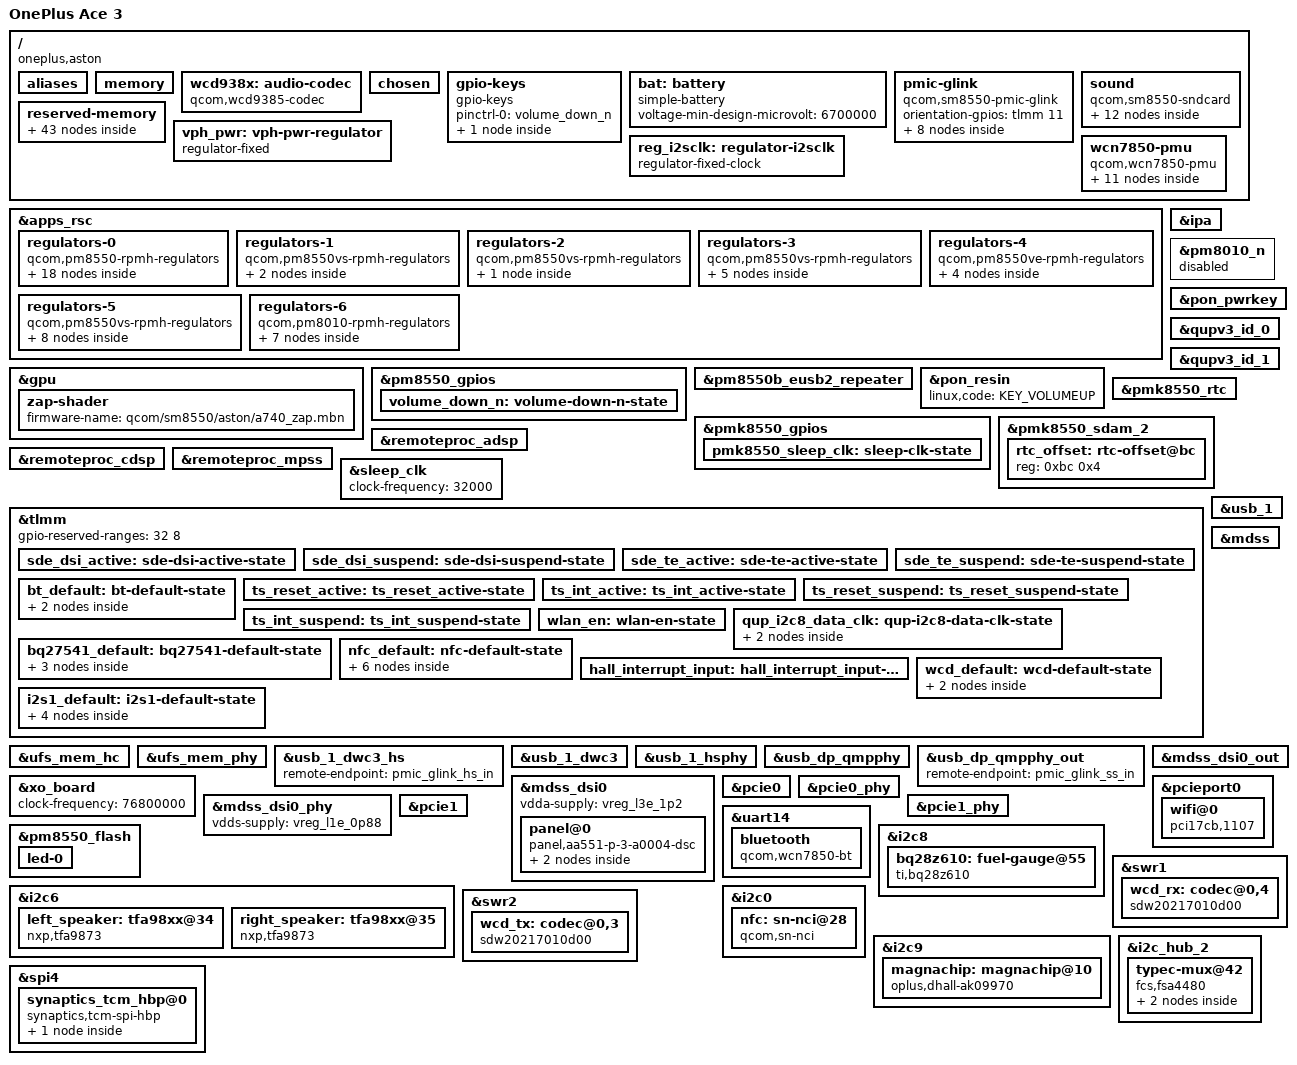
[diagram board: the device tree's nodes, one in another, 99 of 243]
// SPDX-License-Identifier: BSD-3-Clause
/*
 * Copyright (c) 2024, map220v <map220v300@gmail.com>
 */

/dts-v1/;

#include <dt-bindings/arm/qcom,ids.h>
#include <dt-bindings/regulator/qcom,rpmh-regulator.h>
#include <dt-bindings/leds/common.h>
#include "sm8550.dtsi"
#include "pm8010.dtsi"
#include "pm8550.dtsi"
#include "pm8550b.dtsi"
#define PMK8550VE_SID 5
#include "pm8550ve.dtsi"
#include "pm8550vs.dtsi"
#include "pmk8550.dtsi"

/* Remove wrong nodes */
/delete-node/ &rmtfs_mem;
/delete-node/ &adspslpi_mem;
/delete-node/ &mpss_mem;
/delete-node/ &trust_ui_vm_mem;
/delete-node/ &trust_ui_vm_qrtr;
/delete-node/ &oem_vm_vblk0_ring;
/delete-node/ &oem_vm_swiotlb;

/delete-node/ &trust_ui_vm_dump;
/delete-node/ &trust_ui_vm_vblk0_ring;
/delete-node/ &trust_ui_vm_vblk1_ring;
/delete-node/ &trust_ui_vm_swiotlb;
/delete-node/ &oem_vm_mem;

/delete-node/ &sdhc_2;

/ {
	model = "OnePlus Ace 3";
	compatible = "oneplus,aston", "qcom,sm8550";
	chassis-type = "handset";
	qcom,msm-id = <0x207 0x20000 0x207 0x10000 0x218 0x20000 0x218 0x10000>;
	qcom,board-id = <0x10008 0>;

	aliases {
		serial0 = &uart7;
		serial1 = &uart14;
	};
	
	memory {
		ddr_device_type = <0x08>;
		device_type = "memory";
		reg = <0x00 0x80000000 0x00 0xe00000 0x00 0x811d0000 0x00 0x56f90000 0x00 0xd8800000 0x00 0x00 0x00 0xe1bb0000 0x00 0x1e450000 0x08 0x80000000 0x00 0x38700000 0x08 0xc0000000 0x01 0x40000000 0x0a 0x00 0x02 0x00>;
	};
	
	wcd938x: audio-codec {
		compatible = "qcom,wcd9385-codec";

		pinctrl-names = "default", "sleep";
		pinctrl-0 = <&wcd_reset_n_sleep>;
		pinctrl-1 = <&wcd_reset_n_active>;

		qcom,micbias1-microvolt = <2700000>;
		qcom,micbias2-microvolt = <2700000>;
		qcom,micbias3-microvolt = <2700000>;
		qcom,micbias4-microvolt = <2700000>;
		qcom,mbhc-buttons-vthreshold-microvolt = <75000 150000 237000 500000 500000 500000 500000 500000>;
		qcom,mbhc-headset-vthreshold-microvolt = <1700000>;
		qcom,mbhc-headphone-vthreshold-microvolt = <50000>;
		qcom,rx-device = <&wcd_rx>;
		qcom,tx-device = <&wcd_tx>;

		reset-gpios = <&tlmm 108 GPIO_ACTIVE_LOW>;

		vdd-buck-supply = <&vreg_l15b_1p8>;
		vdd-rxtx-supply = <&vreg_l15b_1p8>;
		vdd-io-supply = <&vreg_l15b_1p8>;
		vdd-mic-bias-supply = <&vreg_bob1>;

		#sound-dai-cells = <1>;
	};
	
	chosen {
		#address-cells = <2>;
		#size-cells = <2>;
		ranges;
	};

	gpio-keys {
		compatible = "gpio-keys";

		pinctrl-0 = <&volume_down_n>;
		pinctrl-names = "default";

		key-volume-down {
			label = "Volume Down";
			linux,code = <KEY_VOLUMEDOWN>;
			gpios = <&pm8550_gpios 6 GPIO_ACTIVE_LOW>;
			debounce-interval = <15>;
			linux,can-disable;
			wakeup-source;
		};
	};
	
	bat: battery {
		compatible = "simple-battery";
		voltage-min-design-microvolt = <6700000>;
	};

	pmic-glink {
		compatible = "qcom,sm8550-pmic-glink", "qcom,pmic-glink";
		#address-cells = <1>;
		#size-cells = <0>;
		orientation-gpios = <&tlmm 11 GPIO_ACTIVE_HIGH>;

		connector@0 {
			compatible = "usb-c-connector";
			reg = <0>;
			power-role = "dual";
			data-role = "dual";

			ports {
				#address-cells = <1>;
				#size-cells = <0>;

				port@0 {
					reg = <0>;

					pmic_glink_hs_in: endpoint {
						remote-endpoint = <&usb_1_dwc3_hs>;
					};
				};

				port@1 {
					reg = <1>;

					pmic_glink_ss_in: endpoint {
						remote-endpoint = <&usb_dp_qmpphy_out>;
					};
				};

				port@2 {
					reg = <2>;

					pmic_glink_sbu: endpoint {
						remote-endpoint = <&fsa4480_sbu_mux>;
					};
				};
			};
		};
	};
	
	sound {
		compatible = "qcom,sm8550-sndcard";
		model = "astonsnd";
		audio-routing = "IN1_HPHL", "HPHL_OUT",
				"IN2_HPHR", "HPHR_OUT",
				"AMIC1", "MIC BIAS1",
				"AMIC2", "MIC BIAS2",
				"AMIC3", "MIC BIAS3",
				"AMIC4", "MIC BIAS3",
				"AMIC5", "MIC BIAS4",
				"TX SWR_INPUT0", "ADC1_OUTPUT",
				"TX SWR_INPUT1", "ADC2_OUTPUT",
				"TX SWR_INPUT0", "ADC3_OUTPUT",
				"TX SWR_INPUT1", "ADC4_OUTPUT";

		pinctrl-0 = <&i2s1_default>; 
		pinctrl-names = "default";

		wcd-playback-dai-link {
			link-name = "WCD Playback";

			cpu {
				sound-dai = <&q6apmbedai RX_CODEC_DMA_RX_0>;
			};

			codec {
				sound-dai = <&wcd938x 0>, <&swr1 0>, <&lpass_rxmacro 0>;
			};

			platform {
				sound-dai = <&q6apm>;
			};
		};

		wcd-capture-dai-link {
			link-name = "WCD Capture";

			cpu {
				sound-dai = <&q6apmbedai TX_CODEC_DMA_TX_3>;
			};

			codec {
				sound-dai = <&wcd938x 1>, <&swr2 0>, <&lpass_txmacro 0>;
			};

			platform {
				sound-dai = <&q6apm>;
			};
		};
		
		secondary-rx-dai-link { 
			link-name = "Secondary MI2S Playback"; 
		  
			cpu { 
				sound-dai = <&q6apmbedai SECONDARY_MI2S_RX>; 
			}; 
		  
			platform { 
				sound-dai = <&q6apm>; 
			}; 
		  
			codec { 
				sound-dai = <&left_speaker>, <&right_speaker>; 
			}; 
		};
	};


	reserved-memory {
		#address-cells = <2>;
		#size-cells = <2>;
		ranges;
		
		hyp_mem: hyp-region@80000000 {
			no-map;
			reg = <0x00 0x80000000 0x00 0xa00000>;
		};

		cpusys_vm_mem: cpusys-vm-region@80a00000 {
			no-map;
			reg = <0x00 0x80a00000 0x00 0x400000>;
		};

		/* merged xbl_dt_log, xbl_ramdump, aop_image */
		xbl_dt_log_merged_mem: xbl-dt-log-merged-region@81a00000 {
			no-map;
			reg = <0x00 0x81a00000 0x00 0x260000>;
		};

		aop_cmd_db_mem: aop-cmd-db-region@81c60000 {
			compatible = "qcom,cmd-db";
			no-map;
			reg = <0x00 0x81c60000 0x00 0x20000>;
		};

		/* merged aop_config, tme_crash_dump, tme_log, uefi_log */
		aop_config_merged_mem: aop-config-merged-region@81c80000 {
			no-map;
			reg = <0x00 0x81c80000 0x00 0x74000>;
		};

		/* secdata region can be reused by apps */
		smem: smem@81d00000 {
			no-map;
			reg = <0x00 0x81d00000 0x00 0x200000>;
			hwlocks = <&tcsr_mutex 3>;
			compatible = "qcom,smem";
		};

		adsp_mhi_mem: adsp-mhi-region@81f00000 {
			no-map;
			reg = <0x00 0x81f00000 0x00 0x20000>;
		};

		global_sync_mem: global-sync-region@82600000 {
			no-map;
			reg = <0x00 0x82600000 0x00 0x100000>;
		};

		tz_stat_mem: tz-stat-region@82700000 {
			no-map;
			reg = <0x00 0x82700000 0x00 0x100000>;
		};

		mpss_mem: mpss-region@89800000 {
			no-map;
			reg = <0x00 0x8a800000 0x00 0x10800000>;
		};

		q6_mpss_dtb_mem: q6-mpss-dtb-region@9b000000 {
			no-map;
			reg = <0x00 0x9b000000 0x00 0x80000>;
		};

		ipa_fw_mem: ipa-fw-region@9b080000 {
			no-map;
			reg = <0x00 0x9b080000 0x00 0x10000>;
		};

		ipa_gsi_mem: ipa-gsi-region@9b090000 {
			no-map;
			reg = <0x00 0x9b090000 0x00 0xa000>;
		};

		gpu_micro_code_mem: gpu-micro-code-region@9b09a000 {
			no-map;
			reg = <0x00 0x9b09a000 0x00 0x2000>;
		};

		spss_region_mem: spss-region@9b100000 {
			no-map;
			reg = <0x00 0x9b100000 0x00 0x180000>;
		};

		/* First part of the "SPU secure shared memory" region */
		spu_tz_shared_mem: spu-tz-shared-region@9b280000 {
			no-map;
			reg = <0x00 0x9b280000 0x00 0x60000>;
		};

		/* Second part of the "SPU secure shared memory" region */
		spu_modem_shared_mem: spu-modem-shared-region@9b2e0000 {
			no-map;
			reg = <0x00 0x9b2e0000 0x00 0x20000>;
		};

		camera_mem: camera-region@9b300000 {
			no-map;
			reg = <0x00 0x9b300000 0x00 0x800000>;
		};

		video_mem: video-region@9bb00000 {
			no-map;
			reg = <0x00 0x9bb00000 0x00 0x700000>;
		};

		cvp_mem: cvp-region@9c200000 {
			no-map;
			reg = <0x00 0x9c200000 0x00 0x700000>;
		};

		cdsp_mem: cdsp-region@9c900000 {
			no-map;
			reg = <0x00 0x9c900000 0x00 0x2000000>;
		};

		q6_cdsp_dtb_mem: q6-cdsp-dtb-region@9e900000 {
			no-map;
			reg = <0x00 0x9e900000 0x00 0x80000>;
		};

		q6_adsp_dtb_mem: q6-adsp-dtb-region@9e980000 {
			no-map;
			reg = <0x00 0x9e980000 0x00 0x80000>;
		};

		adspslpi_mem: adspslpi-region@9ea00000 {
			no-map;
			reg = <0x00 0x9ea00000 0x00 0x4880000>;
		};
		
		rmtfs_mem: rmtfs-region@e8100000 {
			compatible = "qcom,rmtfs-mem";
			reg = <0x0 0xe8100000 0x0 0x280000>;
			no-map;

			qcom,client-id = <1>;
			qcom,vmid = <QCOM_SCM_VMID_MSS_MSA>;
		};

		mpss_dsm_mem: mpss-dsm-region@d4d00000 {
			no-map;
			reg = <0x00 0xd4d00000 0x00 0x3300000>;
		};

		tz_reserved_mem: tz-reserved-region@d8000000 {
			no-map;
			reg = <0x00 0xd8000000 0x00 0x100000>;
		};

		xbl_sc_mem: xbl-sc-region@d8100000 {
			no-map;
			reg = <0x00 0xd8100000 0x00 0x40000>;
		};

		cpucp_fw_mem: cpucp-fw-region@d8140000 {
			no-map;
			reg = <0x00 0xd8140000 0x00 0x1c0000>;
		};

		qtee_mem: qtee-region@d8300000 {
			no-map;
			reg = <0x00 0xd8300000 0x00 0x500000>;
		};

		hwfence_shbuf: hwfence-shbuf-region@e6440000 {
			no-map;
			reg = <0x00 0xe6440000 0x00 0x279000>;
		};

		trust_ui_vm_mem: trust-ui-vm-region@f3800000 {
			no-map;
			reg = <0x00 0xf3800000 0x00 0x40ee000>;
		};

		trust_ui_vm_dump: trust-ui-vm-dump-region@f78ee000 {
			no-map;
			reg = <0x00 0xf78ee000 0x00 0x1000>;
		};

		trust_ui_vm_qrtr: trust-ui-vm-qrt-region@f78ef000 {
			no-map;
			reg = <0x00 0xf78ef000 0x00 0x9000>;
		};

		trust_ui_vm_vblk0_ring: trust-ui-vm-vblk0-ring-region@f78f8000 {
			no-map;
			reg = <0x00 0xf78f8000 0x00 0x4000>;
		};

		trust_ui_vm_vblk1_ring: trust-ui-vm-vblk1-ring-region@f78fc000 {
			no-map;
			reg = <0x00 0xf78fc000 0x00 0x4000>;
		};

		trust_ui_vm_swiotlb: trust-ui-vm-swiotlb-region@f7900000 {
			no-map;
			reg = <0x00 0xf7900000 0x00 0x100000>;
		};

		oem_vm_vblk0_ring: oem-vm-vblk0-ring-region@f7afc000 {
			no-map;
			reg = <0x00 0xf7afc000 0x00 0x4000>;
		};

		oem_vm_swiotlb: oem-vm-swiotlb-region@f7b00000 {
			no-map;
			reg = <0x00 0xf7b00000 0x00 0x100000>;
		};

		llcc_lpi_region: llcc_lpi_region@ff800000 {
			no-map;
			reg = <0x00 0xff800000 0x00 0x600000>;
		};
		
		oem_vm_mem: oem-vm-region@f7c00000 {
			reg = <0x00 0xf7c00000 0x00 0x4800000>;
			no-map;
		};

		botloader_mem: botloader_mem@a7605000 {
			reg = <0x00 0xa7605000 0x00 0x8000>;
		};

		device_info_mem: device_info_mem@a4f00000 {
			reg = <0x00 0xa4f00000 0x00 0x8000>;
		};
	};

	vph_pwr: vph-pwr-regulator {
		compatible = "regulator-fixed";
		regulator-name = "vph_pwr";
		regulator-min-microvolt = <3700000>;
		regulator-max-microvolt = <3700000>;

		regulator-always-on;
		regulator-boot-on;
	};
	
	reg_i2sclk: regulator-i2sclk { 
		compatible = "regulator-fixed-clock"; 
		regulator-name = "I2S1"; 
		clocks = <&q6prmcc LPASS_CLK_ID_SEC_MI2S_IBIT LPASS_CLK_ATTRIBUTE_COUPLE_NO>; 
		assigned-clocks = <&q6prmcc LPASS_CLK_ID_SEC_MI2S_IBIT LPASS_CLK_ATTRIBUTE_COUPLE_NO>; 
		assigned-clock-rates = <1536000>; 
	 
		vin-supply = <&vph_pwr>; 
		regulator-always-on; 
		regulator-min-microvolt = <3700000>; 
		regulator-max-microvolt = <3700000>; 
		startup-delay-us = <150000>; 
	 }; 
	
	wcn7850-pmu {
		compatible = "qcom,wcn7850-pmu";

		pinctrl-names = "default";
		pinctrl-0 = <&wlan_en>, <&pmk8550_sleep_clk>;

		wlan-enable-gpios = <&tlmm 80 GPIO_ACTIVE_HIGH>;
		/*
		 * TODO Add bt-enable-gpios once the Bluetooth driver is
		 * converted to using the power sequencer.
		 */

		vdd-supply = <&vreg_s5g_0p8>;
		vddio-supply = <&vreg_l15b_1p8>; 
		vddaon-supply = <&vreg_s2g_0p8>;
		vdddig-supply = <&vreg_s4e_0p9>;
		vddrfa1p2-supply = <&vreg_s4g_1p3>;
		vddrfa1p8-supply = <&vreg_s6g_1p8>;

		regulators {
			vreg_pmu_rfa_cmn: ldo0 {
				regulator-name = "vreg_pmu_rfa_cmn";
			};

			vreg_pmu_aon_0p59: ldo1 {
				regulator-name = "vreg_pmu_aon_0p59";
			};

			vreg_pmu_wlcx_0p8: ldo2 {
				regulator-name = "vreg_pmu_wlcx_0p8";
			};

			vreg_pmu_wlmx_0p85: ldo3 {
				regulator-name = "vreg_pmu_wlmx_0p85";
			};

			vreg_pmu_btcmx_0p85: ldo4 {
				regulator-name = "vreg_pmu_btcmx_0p85";
			};

			vreg_pmu_rfa_0p8: ldo5 {
				regulator-name = "vreg_pmu_rfa_0p8";
			};

			vreg_pmu_rfa_1p2: ldo6 {
				regulator-name = "vreg_pmu_rfa_1p2";
			};

			vreg_pmu_rfa_1p8: ldo7 {
				regulator-name = "vreg_pmu_rfa_1p8";
			};

			vreg_pmu_pcie_0p9: ldo8 {
				regulator-name = "vreg_pmu_pcie_0p9";
			};

			vreg_pmu_pcie_1p8: ldo9 {
				regulator-name = "vreg_pmu_pcie_1p8";
			};
		};
	};
};

&apps_rsc {
	regulators-0 {
		compatible = "qcom,pm8550-rpmh-regulators";
		qcom,pmic-id = "b";

		vdd-bob1-supply = <&vph_pwr>;
		vdd-bob2-supply = <&vph_pwr>;
		vdd-l1-l4-l10-supply = <&vreg_s6g_1p8>;
		vdd-l2-l13-l14-supply = <&vreg_bob1>;
		vdd-l3-supply = <&vreg_s4g_1p3>;
		vdd-l5-l16-supply = <&vreg_bob1>;
		vdd-l6-l7-supply = <&vreg_bob1>;
		vdd-l8-l9-supply = <&vreg_bob1>;
		vdd-l11-supply = <&vreg_s4g_1p3>;
		vdd-l12-supply = <&vreg_s6g_1p8>;
		vdd-l15-supply = <&vreg_s6g_1p8>;
		vdd-l17-supply = <&vreg_bob2>;

		vreg_bob1: bob1 {
			regulator-name = "vreg_bob1";
			regulator-min-microvolt = <3008000>;
			regulator-max-microvolt = <3960000>;
			regulator-initial-mode = <RPMH_REGULATOR_MODE_HPM>;
		};

		vreg_bob2: bob2 {
			regulator-name = "vreg_bob2";
			regulator-min-microvolt = <2704000>;
			regulator-max-microvolt = <3008000>;
			regulator-initial-mode = <RPMH_REGULATOR_MODE_HPM>;
		};

		vreg_l1b_1p8: ldo1 {
			regulator-name = "vreg_l1b_1p8";
			regulator-min-microvolt = <1800000>;
			regulator-max-microvolt = <1800000>;
			regulator-initial-mode = <RPMH_REGULATOR_MODE_HPM>;
		};

		vreg_l2b_3p0: ldo2 {
			regulator-name = "vreg_l2b_3p0";
			regulator-min-microvolt = <3008000>;
			regulator-max-microvolt = <3008000>;
			regulator-initial-mode = <RPMH_REGULATOR_MODE_HPM>;
		};

		vreg_l4b_1p8: ldo4 {
			regulator-name = "vreg_l4b_1p8";
			regulator-min-microvolt = <1800000>;
			regulator-max-microvolt = <1800000>;
			regulator-initial-mode = <RPMH_REGULATOR_MODE_HPM>;
		};

		vreg_l5b_3p1: ldo5 {
			regulator-name = "vreg_l5b_3p1";
			regulator-min-microvolt = <3104000>;
			regulator-max-microvolt = <3104000>;
			regulator-initial-mode = <RPMH_REGULATOR_MODE_HPM>;
		};

		vreg_l6b_1p8: ldo6 {
			regulator-name = "vreg_l6b_1p8";
			regulator-min-microvolt = <1800000>;
			regulator-max-microvolt = <3008000>;
			regulator-initial-mode = <RPMH_REGULATOR_MODE_HPM>;
		};

		vreg_l7b_1p8: ldo7 {
			regulator-name = "vreg_l7b_1p8";
			regulator-min-microvolt = <1800000>;
			regulator-max-microvolt = <3008000>;
			regulator-initial-mode = <RPMH_REGULATOR_MODE_HPM>;
		};

		vreg_l8b_1p8: ldo8 {
			regulator-name = "vreg_l8b_1p8";
			regulator-min-microvolt = <1800000>;
			regulator-max-microvolt = <1800000>;
			regulator-initial-mode = <RPMH_REGULATOR_MODE_HPM>;
			regulator-always-on;
			regulator-boot-on;
		};

		vreg_l9b_3p3: ldo9 {
			regulator-name = "vreg_l9b_3p3";
			regulator-min-microvolt = <2960000>;
			regulator-max-microvolt = <3008000>;
			regulator-initial-mode = <RPMH_REGULATOR_MODE_HPM>;
		};

		vreg_l10b_1p8: ldo10 {
			regulator-name = "vreg_l10b_1p8";
			regulator-min-microvolt = <1800000>;
			regulator-max-microvolt = <1800000>;
			regulator-initial-mode = <RPMH_REGULATOR_MODE_HPM>;
		};

		vreg_l11b_1p2: ldo11 {
			regulator-name = "vreg_l11b_1p2";
			regulator-min-microvolt = <1200000>;
			regulator-max-microvolt = <1504000>;
			regulator-initial-mode = <RPMH_REGULATOR_MODE_HPM>;
		};

		vreg_l12b_1p8: ldo12 {
			regulator-name = "vreg_l12b_1p8";
			regulator-min-microvolt = <1800000>;
			regulator-max-microvolt = <1800000>;
			regulator-initial-mode = <RPMH_REGULATOR_MODE_HPM>;
		};

		vreg_l13b_3p3: ldo13 {
			regulator-name = "vreg_l13b_3p3";
			regulator-min-microvolt = <3000000>;
			regulator-max-microvolt = <3200000>;
			regulator-initial-mode = <RPMH_REGULATOR_MODE_HPM>;
		};

		vreg_l14b_3p2: ldo14 {
			regulator-name = "vreg_l14b_3p2";
			regulator-min-microvolt = <2800000>;
			regulator-max-microvolt = <3200000>;
			regulator-initial-mode = <RPMH_REGULATOR_MODE_HPM>;
		};
		
		vreg_l15b_1p8: ldo15 {
			regulator-name = "vreg_l15b_1p8";
			regulator-min-microvolt = <1800000>;
			regulator-max-microvolt = <1800000>;
			regulator-initial-mode = <RPMH_REGULATOR_MODE_HPM>;
		};

		vreg_l16b_2p8: ldo16 {
			regulator-name = "vreg_l16b_2p8";
			regulator-min-microvolt = <2800000>;
			regulator-max-microvolt = <2800000>;
			regulator-initial-mode = <RPMH_REGULATOR_MODE_HPM>;
		};

		vreg_l17b_2p5: ldo17 {
			regulator-name = "vreg_l17b_2p5";
			regulator-min-microvolt = <2504000>;
			regulator-max-microvolt = <2504000>;
			regulator-initial-mode = <RPMH_REGULATOR_MODE_HPM>;
		};
	};

	regulators-1 {
		compatible = "qcom,pm8550vs-rpmh-regulators";
		qcom,pmic-id = "c";

		vdd-l3-supply = <&vreg_s4e_0p9>;
		
		
		vreg_l1c_0p91: ldo1 {
			regulator-name = "vreg_l1c_0p9";
			regulator-min-microvolt = <1200000>;
			regulator-max-microvolt = <1200000>;
			regulator-initial-mode = <RPMH_REGULATOR_MODE_HPM>;
		};

		vreg_l3c_0p91: ldo3 {
			regulator-name = "vreg_l3c_0p9";
			regulator-min-microvolt = <880000>;
			regulator-max-microvolt = <912000>;
			regulator-initial-mode = <RPMH_REGULATOR_MODE_HPM>;
		};
	};

	regulators-2 {
		compatible = "qcom,pm8550vs-rpmh-regulators";
		qcom,pmic-id = "d";

		vdd-l1-supply = <&vreg_s4e_0p9>;

		vreg_l1d_0p88: ldo1 {
			regulator-name = "vreg_l1d_0p88";
			regulator-min-microvolt = <880000>;
			regulator-max-microvolt = <920000>;
			regulator-initial-mode = <RPMH_REGULATOR_MODE_HPM>;
		};
	};

	regulators-3 {
		compatible = "qcom,pm8550vs-rpmh-regulators";
		qcom,pmic-id = "e";

		vdd-l1-supply = <&vreg_s4e_0p9>;
		vdd-l2-supply = <&vreg_s4e_0p9>;
		vdd-l3-supply = <&vreg_s4g_1p3>;
		vdd-s4-supply = <&vph_pwr>;
		vdd-s5-supply = <&vph_pwr>;

		vreg_s4e_0p9: smps4 {
			regulator-name = "vreg_s4e_0p9";
			regulator-min-microvolt = <904000>;
			regulator-max-microvolt = <984000>;
			regulator-initial-mode = <RPMH_REGULATOR_MODE_HPM>;
		};

		vreg_s5e_1p1: smps5 {
			regulator-name = "vreg_s5e_1p1";
			regulator-min-microvolt = <1008000>;
			regulator-max-microvolt = <1120000>;
			regulator-initial-mode = <RPMH_REGULATOR_MODE_HPM>;
		};

		vreg_l1e_0p88: ldo1 {
			regulator-name = "vreg_l1e_0p88";
			regulator-min-microvolt = <880000>;
			regulator-max-microvolt = <912000>;
			regulator-initial-mode = <RPMH_REGULATOR_MODE_HPM>;
		};

		vreg_l2e_0p9: ldo2 {
			regulator-name = "vreg_l2e_0p9";
			regulator-min-microvolt = <864000>;
			regulator-max-microvolt = <970000>;
			regulator-initial-mode = <RPMH_REGULATOR_MODE_HPM>;
		};

		vreg_l3e_1p2: ldo3 {
			regulator-name = "vreg_l3e_1p2";
			regulator-min-microvolt = <1200000>;
			regulator-max-microvolt = <1200000>;
			regulator-initial-mode = <RPMH_REGULATOR_MODE_HPM>;
		};
	};

	regulators-4 {
		compatible = "qcom,pm8550ve-rpmh-regulators";
		qcom,pmic-id = "f";

		vdd-l1-supply = <&vreg_s4e_0p9>;
		vdd-l2-supply = <&vreg_s4e_0p9>;
		vdd-l3-supply = <&vreg_s4e_0p9>;
		vdd-s4-supply = <&vph_pwr>;

		vreg_s4f_0p5: smps4 {
			regulator-name = "vreg_s4f_0p5";
			regulator-min-microvolt = <300000>;
			regulator-max-microvolt = <700000>;
			regulator-initial-mode = <RPMH_REGULATOR_MODE_HPM>;
		};

		vreg_l1f_0p9: ldo1 {
			regulator-name = "vreg_l1f_0p9";
			regulator-min-microvolt = <880000>;
			regulator-max-microvolt = <912000>;
			regulator-initial-mode = <RPMH_REGULATOR_MODE_HPM>;
		};

		vreg_l2f_0p88: ldo2 {
			regulator-name = "vreg_l2f_0p88";
			regulator-min-microvolt = <880000>;
			regulator-max-microvolt = <912000>;
			regulator-initial-mode = <RPMH_REGULATOR_MODE_HPM>;
		};

		vreg_l3f_0p91: ldo3 {
			regulator-name = "vreg_l3f_0p91";
			regulator-min-microvolt = <880000>;
			regulator-max-microvolt = <912000>;
			regulator-initial-mode = <RPMH_REGULATOR_MODE_HPM>;
		};
	};

	regulators-5 {
		compatible = "qcom,pm8550vs-rpmh-regulators";
		qcom,pmic-id = "g";

		vdd-l1-supply = <&vreg_s4g_1p3>;
		vdd-l2-supply = <&vreg_s4g_1p3>;
		vdd-l3-supply = <&vreg_s4g_1p3>;
		vdd-s1-supply = <&vph_pwr>;
		vdd-s2-supply = <&vph_pwr>;
		vdd-s3-supply = <&vph_pwr>;
		vdd-s4-supply = <&vph_pwr>;
		vdd-s5-supply = <&vph_pwr>;
		vdd-s6-supply = <&vph_pwr>;

		vreg_s1g_1p2: smps1 {
			regulator-name = "vreg_s1g_1p2";
			regulator-min-microvolt = <1200000>;
			regulator-max-microvolt = <1300000>;
			regulator-initial-mode = <RPMH_REGULATOR_MODE_HPM>;
		};

		vreg_s2g_0p8: smps2 {
			regulator-name = "vreg_s2g_0p8";
			regulator-min-microvolt = <500000>;
			regulator-max-microvolt = <1036000>;
			regulator-initial-mode = <RPMH_REGULATOR_MODE_HPM>;
		};

		vreg_s4g_1p3: smps4 {
			regulator-name = "vreg_s4g_1p3";
			regulator-min-microvolt = <1200000>;
			regulator-max-microvolt = <1352000>;
			regulator-initial-mode = <RPMH_REGULATOR_MODE_HPM>;
		};

		vreg_s5g_0p8: smps5 {
			regulator-name = "vreg_s5g_0p8";
			regulator-min-microvolt = <500000>;
			regulator-max-microvolt = <1004000>;
			regulator-initial-mode = <RPMH_REGULATOR_MODE_HPM>;
		};

		vreg_s6g_1p8: smps6 {
			regulator-name = "vreg_s6g_1p8";
			regulator-min-microvolt = <1800000>;
			regulator-max-microvolt = <2000000>;
			regulator-initial-mode = <RPMH_REGULATOR_MODE_HPM>;
		};

		vreg_l1g_1p2: ldo1 {
			regulator-name = "vreg_l1g_1p2";
			regulator-min-microvolt = <1144000>;
			regulator-max-microvolt = <1256000>;
			regulator-initial-mode = <RPMH_REGULATOR_MODE_HPM>;
		};

		vreg_l2g_1p2: ldo2 {
			regulator-name = "vreg_l2g_1p2";
			regulator-min-microvolt = <1050000>;
			regulator-max-microvolt = <1200000>;
			regulator-initial-mode = <RPMH_REGULATOR_MODE_HPM>;
		};

		vreg_l3g_1p2: ldo3 {
			regulator-name = "vreg_l3g_1p2";
			regulator-min-microvolt = <1200000>;
			regulator-max-microvolt = <1200000>;
			regulator-initial-mode = <RPMH_REGULATOR_MODE_HPM>;
		};
	};

	regulators-6 {
		compatible = "qcom,pm8010-rpmh-regulators";
		qcom,pmic-id = "m";

		vdd-l1-l2-supply = <&vreg_s4g_1p3>;
		vdd-l3-l4-supply = <&vreg_bob2>;
		vdd-l5-supply = <&vreg_s6g_1p8>;
		vdd-l6-supply = <&vreg_s6g_1p8>;
		vdd-l7-supply = <&vreg_bob1>;

		vreg_l1m_1p2: ldo1 {
			regulator-name = "vreg_l1m_1p2";
			regulator-min-microvolt = <1200000>;
			regulator-max-microvolt = <1200000>;
			regulator-initial-mode = <RPMH_REGULATOR_MODE_HPM>;
		};

		vreg_l2m_1p08: ldo2 {
			regulator-name = "vreg_l2m_1p08";
			regulator-min-microvolt = <1200000>;
			regulator-max-microvolt = <1200000>;
			regulator-initial-mode = <RPMH_REGULATOR_MODE_HPM>;
		};

		vreg_l3m_2p8: ldo3 {
			regulator-name = "vreg_l3m_2p8";
			regulator-min-microvolt = <2200000>;
			regulator-max-microvolt = <3304000>;
			regulator-initial-mode = <RPMH_REGULATOR_MODE_HPM>;
		};

		vreg_l4m_2p8: ldo4 {
			regulator-name = "vreg_l4m_2p8";
			regulator-min-microvolt = <1800000>;
			regulator-max-microvolt = <3304000>;
			regulator-initial-mode = <RPMH_REGULATOR_MODE_HPM>;
		};

		vreg_l5m_1p8: ldo5 {
			regulator-name = "vreg_l5m_1p8";
			regulator-min-microvolt = <1800000>;
			regulator-max-microvolt = <1800000>;
			regulator-initial-mode = <RPMH_REGULATOR_MODE_HPM>;
		};

		vreg_l6m_2p8: ldo6 {
			regulator-name = "vreg_l6m_2p8";
			regulator-min-microvolt = <1800000>;
			regulator-max-microvolt = <3304000>;
			regulator-initial-mode = <RPMH_REGULATOR_MODE_HPM>;
		};

		vreg_l7m_2p85: ldo7 {
			regulator-name = "vreg_l7m_2p85";
			regulator-min-microvolt = <1800000>;
			regulator-max-microvolt = <3152000>;
			regulator-initial-mode = <RPMH_REGULATOR_MODE_HPM>;
		};
	};
};



&ipa {
	qcom,gsi-loader = "self";
	memory-region = <&ipa_gsi_mem>;
	firmware-name = "qcom/sm8550/aston/ipa_fws.mbn";
	status = "okay";
};

&gpu {
	status = "okay";

	zap-shader {
		firmware-name = "qcom/sm8550/aston/a740_zap.mbn";
	};
};

&pm8010_n {
	status = "disabled";
};

&pm8550_gpios {
	volume_down_n: volume-down-n-state {
		pins = "gpio6";
		function = "normal";
		power-source = <1>;
		bias-pull-up;
		input-enable;
	};
};

&pm8550b_eusb2_repeater {
	vdd18-supply = <&vreg_l15b_1p8>;
	vdd3-supply = <&vreg_l5b_3p1>;
};

&pon_pwrkey {
	status = "okay";
	interrupts = <0x0 0x13 0x7 IRQ_TYPE_EDGE_BOTH>;
    linux,code = <KEY_POWER>;
};

&pon_resin {
	linux,code = <KEY_VOLUMEUP>;

	status = "okay";
};

&pmk8550_gpios {
	pmk8550_sleep_clk: sleep-clk-state {
		pins = "gpio3";
		function = "func1";
		input-disable;
		output-enable;
		bias-disable;
		power-source = <0>;
	};
};

&qupv3_id_0 {
	status = "okay";
};

&qupv3_id_1 {
	status = "okay";
};

&pmk8550_rtc {
	nvmem-cells = <&rtc_offset>;
	nvmem-cell-names = "offset";
};

&pmk8550_sdam_2 {
	rtc_offset: rtc-offset@bc {
		reg = <0xbc 0x4>;
	};
};

&remoteproc_adsp {
	firmware-name = "qcom/sm8550/aston/adsp.mbn",
			"qcom/sm8550/aston/adsp_dtb.mbn";
	status = "okay";
};

&remoteproc_cdsp {
	firmware-name = "qcom/sm8550/aston/cdsp.mbn",
			"qcom/sm8550/aston/cdsp_dtb.mbn";
	status = "okay";
};

&remoteproc_mpss {
	firmware-name = "qcom/sm8550/aston/modem.mbn",
			"qcom/sm8550/aston/modem_dtb.mbn";
	status = "okay";
};

&sleep_clk {
	clock-frequency = <32000>;
};

&tlmm {
	gpio-reserved-ranges = <32 8>;

	sde_dsi_active: sde-dsi-active-state {
		pins = "gpio133";
		function = "gpio";
		drive-strength = <8>;
		bias-disable;
	};

	sde_dsi_suspend: sde-dsi-suspend-state {
		pins = "gpio133";
		function = "gpio";
		drive-strength = <2>;
		bias-pull-down;
	};
	
	sde_te_active: sde-te-active-state {
		pins = "gpio86";
		function = "mdp_vsync";
		drive-strength = <2>;
		bias-pull-down;
	};

	sde_te_suspend: sde-te-suspend-state {
		pins = "gpio86";
		function = "mdp_vsync";
		drive-strength = <2>;
		bias-pull-down;
	};

	bt_default: bt-default-state {
		bt-en-pins {
			pins = "gpio81";
			function = "gpio";
			drive-strength = <16>;
			bias-disable;
		};

		sw-ctrl-pins {
			pins = "gpio82";
			function = "gpio";
			bias-pull-down;
		};
	};
	
	ts_reset_active: ts_reset_active-state {
		pins = "gpio24";
		function = "gpio";
		bias-disable;
		output-low;
		drive-strength = <8>;
	};

	ts_int_active: ts_int_active-state {
		pins = "gpio25";
		function = "gpio";
		bias-pull-up;
		drive-strength = <8>;
		input-enable;
	};
	
	ts_reset_suspend: ts_reset_suspend-state {
		pins = "gpio24";
		function = "gpio";
		bias-pull-down;
		drive-strength = <2>;
	};

	ts_int_suspend: ts_int_suspend-state {
		pins = "gpio25";
		function = "gpio";
		bias-pull-down;
		drive-strength = <2>;
	};

	wlan_en: wlan-en-state {
		pins = "gpio80";
		function = "gpio";
		drive-strength = <8>;
		bias-pull-down;
	};

	qup_i2c8_data_clk: qup-i2c8-data-clk-state {
		scl-pins {
			pins = "gpio1";
			function = "qup2_se0_l1_mirb";
			drive-strength = <2>;
			bias-pull-up = <2200>;
		};

		sda-pins {
			pins = "gpio0";
			function = "qup2_se0_l0_mirb";
			drive-strength = <2>;
			bias-pull-up = <2200>;
		};
	};

	bq27541_default: bq27541-default-state {
		bq27541_id_not_pull: bq27541_id_not_pull-state {
			pins = "gpio73";
			function = "gpio";
			drive-strength = <2>;
			bias-disable;
		};
		
		bq27541_id_pull_up: bq27541_id_pull_up-state {
			pins = "gpio73";
			function = "gpio";
			drive-strength = <2>;
			bias-pull-up;
		};
		
		bq27541_id_pull_down: bq27541_id_pull_down-state {
			pins = "gpio73";
			function = "gpio";
			drive-strength = <2>;
			bias-pull-down;
		};
	};
	
	nfc_default: nfc-default-state {
		nfc_int_active: nfc_int_active-state {
			pins = "gpio55";
			function = "gpio";
			drive-strength = <2>;
			bias-pull-up;
		};
		nfc_enable_active: nfc_enable_active-state {
			pins = "gpio30";
			function = "gpio";
			drive-strength = <2>;
			bias-pull-up;
		};
		nfc_clk_req_active: nfc_clk_req_active-state {
			pins = "gpio31";
			function = "gpio";
			drive-strength = <2>;
			bias-pull-up;
		};
		nfc_int_suspend: nfc_int_suspend-state {
			pins = "gpio55";
			function = "gpio";
			drive-strength = <2>;
			bias-pull-up;
		};
		nfc_enable_suspend: nfc_enable_suspend-state {
			pins = "gpio30";
			function = "gpio";
			drive-strength = <2>;
			bias-disable;
		};
		nfc_clk_req_suspend: nfc_clk_req_suspend-state {
			pins = "gpio31";
			function = "gpio";
			drive-strength = <2>;
			bias-disable;
		};
	};
	
	hall_interrupt_input: hall_interrupt_input-state {
		pins = "gpio17";
		function = "gpio";
		drive-strength = <2>;
		bias-pull-up;
	};
	
	wcd_default: wcd-default-state {
		wcd_reset_n_active: wcd-reset-n-active-state {
			pins = "gpio108";
			function = "gpio";
			drive-strength = <4>;
			output-high;
		};
		wcd_reset_n_sleep: wcd-reset-n-sleep-state {
			pins = "gpio108";
			function = "gpio";
			drive-strength = <4>;
			bias-disable;
			output-low;
		};
	};
	
	i2s1_default: i2s1-default-state { 
		sck-pins { 
			pins = "gpio121"; 
			function = "i2s1_sck"; 
			drive-strength = <6>; 
			input-enable;
			bias-disable; 
		}; 
	 
		data0-pins { 
			pins = "gpio122"; 
			function = "i2s1_data0"; 
			drive-strength = <6>; 
			input-enable;
			bias-disable; 
		}; 
	 
		ws-pins { 
			pins = "gpio123"; 
			function = "i2s1_ws"; 
			drive-strength = <6>; 
			input-enable;
			bias-disable; 
		}; 
	 
		data1-pins { 
			pins = "gpio124"; 
			function = "i2s1_data1"; 
			drive-strength = <6>; 
			input-enable;
			bias-pull-down; 
		}; 
	};
};

&ufs_mem_hc {
	reset-gpios = <&tlmm 210 GPIO_ACTIVE_LOW>;
	vcc-supply = <&vreg_l17b_2p5>;
	vcc-max-microamp = <1300000>;
	vccq-supply = <&vreg_l1g_1p2>;
	vccq-max-microamp = <1200000>;
	vdd-hba-supply = <&vreg_l3g_1p2>;

	status = "okay";
};

&ufs_mem_phy {
	vdda-phy-supply = <&vreg_l1d_0p88>;
	vdda-pll-supply = <&vreg_l3e_1p2>;

	status = "okay";
};

&usb_1 {
	status = "okay";
};

&usb_1_dwc3_hs {
	remote-endpoint = <&pmic_glink_hs_in>;
};

&usb_1_dwc3 {
	snps,disable-clk-gating;
	snps,ssp-u3-u0-quirk;
	dr_mode = "otg";
	maximum-speed = "high-speed";
};

&usb_1_hsphy {
	vdd-supply = <&vreg_l1e_0p88>;
	vdda12-supply = <&vreg_l3e_1p2>;

	phys = <&pm8550b_eusb2_repeater>;

	status = "okay";
};

&usb_dp_qmpphy {
	vdda-phy-supply = <&vreg_l3e_1p2>;
	vdda-pll-supply = <&vreg_l3f_0p91>;

	status = "okay";
};

&usb_dp_qmpphy_out {
	remote-endpoint = <&pmic_glink_ss_in>;
};

&xo_board {
	clock-frequency = <76800000>;
};

&mdss {
	status = "okay";
};

&mdss_dsi0 {
	vdda-supply = <&vreg_l3e_1p2>;
	status = "okay";
	
	panel@0 {
		compatible = "panel,aa551-p-3-a0004-dsc";
		reg = <0>;
		
		pinctrl-names = "default", "sleep";
		pinctrl-0 = <&sde_dsi_active>, <&sde_te_active>;
		pinctrl-1 = <&sde_dsi_suspend>, <&sde_te_suspend>;

		vddio-supply = <&vreg_l12b_1p8>;
		vci-supply = <&vreg_l13b_3p3>;
		
		reset-gpios = <&tlmm 133 GPIO_ACTIVE_LOW>;

		port {
			panel_in: endpoint {
				remote-endpoint = <&mdss_dsi0_out>;
			};
		};
	};
};

&mdss_dsi0_out {
	status = "okay";
	data-lanes = <0 1 2 3>;
	remote-endpoint = <&panel_in>;
};

&mdss_dsi0_phy {
	vdds-supply = <&vreg_l1e_0p88>;
	status = "okay";
};

&pcie0 {
	wake-gpios = <&tlmm 96 GPIO_ACTIVE_HIGH>;
	perst-gpios = <&tlmm 94 GPIO_ACTIVE_LOW>;

	pinctrl-names = "default";
	pinctrl-0 = <&pcie0_default_state>;

	status = "okay";
};

&pcieport0 {
	status = "okay";
	
	wifi@0 {
		compatible = "pci17cb,1107";
		reg = <0x10000 0x0 0x0 0x0 0x0>;

		vddrfacmn-supply = <&vreg_pmu_rfa_cmn>;
		vddaon-supply = <&vreg_pmu_aon_0p59>;
		vddwlcx-supply = <&vreg_pmu_wlcx_0p8>;
		vddwlmx-supply = <&vreg_pmu_wlmx_0p85>;
		vddrfa0p8-supply = <&vreg_pmu_rfa_0p8>;
		vddrfa1p2-supply = <&vreg_pmu_rfa_1p2>;
		vddrfa1p8-supply = <&vreg_pmu_rfa_1p8>;
		vddpcie0p9-supply = <&vreg_pmu_pcie_0p9>;
		vddpcie1p8-supply = <&vreg_pmu_pcie_1p8>;
		status = "okay";
	};
};

&pcie0_phy {
	vdda-phy-supply = <&vreg_l1e_0p88>;
	vdda-pll-supply = <&vreg_l3e_1p2>;

	status = "okay";
};

&pcie1 {
	wake-gpios = <&tlmm 99 GPIO_ACTIVE_HIGH>;
	perst-gpios = <&tlmm 97 GPIO_ACTIVE_LOW>;

	pinctrl-names = "default";
	pinctrl-0 = <&pcie1_default_state>;

	status = "okay";
};

&pcie1_phy {
	vdda-phy-supply = <&vreg_l3c_0p91>;
	vdda-pll-supply = <&vreg_l3e_1p2>;
	vdda-qref-supply = <&vreg_l1e_0p88>;

	status = "okay";
};

&uart14 {
	status = "okay";

	bluetooth {
		compatible = "qcom,wcn7850-bt";

		local-bd-address = [ c2 59 96 e0 ca 00 ];

		vddio-supply = <&vreg_l15b_1p8>;
		vddaon-supply = <&vreg_s4e_0p9>;
		vdddig-supply = <&vreg_s4e_0p9>;
		vddrfa0p8-supply = <&vreg_s4e_0p9>;
		vddrfa1p2-supply = <&vreg_s4g_1p3>;
		vddrfa1p9-supply = <&vreg_s6g_1p8>;

		max-speed = <3200000>;

		enable-gpios = <&tlmm 81 GPIO_ACTIVE_HIGH>;
		swctrl-gpios = <&tlmm 82 GPIO_ACTIVE_HIGH>;

		pinctrl-0 = <&bt_default>;
		pinctrl-names = "default";
	};
};

&pm8550_flash {
	status = "okay";
	
	led-0 {
		function = LED_FUNCTION_FLASH;
		color = <LED_COLOR_ID_WHITE>;
		led-sources = <1>, <4>;
		led-max-microamp = <500000>;
		flash-max-microamp = <2000000>;
		flash-max-timeout-us = <1280000>;
		function-enumerator = <0>;
	};
};

&i2c8 {
	status = "okay";
	bq28z610: fuel-gauge@55 {
		compatible = "ti,bq28z610";
		reg = <0x55>;
		pinctrl-names = "id_not_pull", "id_pull_up", "id_pull_down";
		pinctrl-0 = <&bq27541_id_not_pull>;
		pinctrl-1 = <&bq27541_id_pull_up>;
		pinctrl-2 = <&bq27541_id_pull_down>;
		monitored-battery = <&bat>;
	};
};

&i2c6 {
	status = "okay";
	left_speaker: tfa98xx@34 {
		is_use_freq = <1>;
		tfa_channel = <0>;
		tfa_default_mohm = <6000>;
		tfa_max_range = <8000>;
		tfa_min_range = <5000>;
		vdd-supply = <&vreg_l15b_1p8>;
		reset-gpio = <&tlmm 56 GPIO_ACTIVE_HIGH>;
		reg = <0x34>;
		compatible = "nxp,tfa9873";
		dummy-supply = <&reg_i2sclk>;
		#sound-dai-cells = <0>;
	};

	right_speaker: tfa98xx@35 {
		is_use_freq = <1>;
		tfa_channel = <1>;
		tfa_default_mohm = <6000>;
		tfa_max_range = <8000>;
		tfa_min_range = <5000>;
		vdd-supply = <&vreg_l15b_1p8>;
		reset-gpio = <&tlmm 173 GPIO_ACTIVE_HIGH>;
		reg = <0x35>;
		compatible = "nxp,tfa9873";
		dummy-supply = <&reg_i2sclk>;
		#sound-dai-cells = <0>;
	};
};

&swr1 {
	status = "okay";
	wcd_rx: codec@0,4 {
		compatible = "sdw20217010d00";
		reg = <0 4>;
		qcom,rx-port-mapping = <1 2 3 4 5>;
	};
};

&swr2 {
	status = "okay";
	wcd_tx: codec@0,3 {
		compatible = "sdw20217010d00";
		reg = <0 3>;
		qcom,tx-port-mapping = <2 2 3 4>;
	};
};
&i2c0 {
	status = "okay";
	nfc: sn-nci@28 {
		compatible = "qcom,sn-nci", "nxp,nxp-nci-i2c";
		reg = <0x28>;
		qcom,sn-irq = <&tlmm 55 GPIO_ACTIVE_HIGH>;
		enable-gpios = <&tlmm 30 GPIO_ACTIVE_HIGH>;
		qcom,sn-clkreq = <&tlmm 31 GPIO_ACTIVE_HIGH>;
		interrupt-parent = <&tlmm>;
		interrupts = <55 0>;
		interrupt-names = "nfc_irq";
		pinctrl-names = "default","sleep";
		pinctrl-0 = <&nfc_int_active &nfc_enable_active &nfc_clk_req_active>;
		pinctrl-1 = <&nfc_int_suspend &nfc_enable_suspend &nfc_clk_req_suspend>;
	};
};

&i2c9 {
	status = "okay";
	magnachip: magnachip@10 {
		compatible = "oplus,dhall-ak09970";
		reg = <0x10>;
		vcc_1v8-supply = <&vreg_l1b_1p8>;
		magnachip,init-interval = <200>;
		interrupt-parent = <&tlmm>;
		interrups = <17 2>;
		threeaxis_hall_support;
		dhall,irq-gpio = <&tlmm 17 0x2008>;
		pinctrl-names = "hall_interrupt_input";
		pinctrl-0 = <&hall_interrupt_input>;
		interf_stable_limit = <700 700 700>;
		interf_judege_limit = <4000 4000>;
		interf_up_tolen = <3700 3700 3000 3000>;
		interf_mid_tolen = <3000 3000 3000 3000>;
		interf_down_tolen = <3000 3000 3700 3700>;
		position_judge_tolen = <4000 5000>;
		default_position_xtolen = <3000 3000>;
	};
};

&i2c_hub_2 {
	status = "okay";
	typec-mux@42 {
		compatible = "fcs,fsa4480";
		reg = <0x42>;

		vcc-supply = <&vreg_bob1>;

		mode-switch;
		orientation-switch;

		port {
			fsa4480_sbu_mux: endpoint {
				remote-endpoint = <&pmic_glink_sbu>;
			};
		};
	};
};

&spi4 {
	status = "okay";
	synaptics_tcm_hbp@0 {
		compatible = "synaptics,tcm-spi-hbp";
		reg = <0x0>;
		chip-name = "S3910";
		status = "okay";
		spi-max-frequency = <19000000>;
		qcom,rt;
		interrupt-parent = <&tlmm>;
		interrupts = <25 0x2008>;
		synaptics,avdd-gpio = <&tlmm 10 0x1>;
		vdd-supply = <&vreg_l4b_1p8>;
		synaptics,vdd-name = "vdd";
		synaptics,irq-gpio = <&tlmm 25 0x2008>;
		synaptics,reset-gpio = <&tlmm 24 0x1>;
		pinctrl-names = "ts_spi_active", "ts_spi_suspend";
		pinctrl-0 = <&ts_int_active &ts_reset_active>;
		pinctrl-1 = <&ts_int_suspend &ts_reset_suspend>;
		platform_support_project = <0x5cf9 0x5d35 0x5d36 0x5d37>;
		platform_support_project_dir = <0x5cf9 0x5cf9 0x5cf9 0x5cf9>;
		platform_support_project_commandline = "mdss_dsi_panel_AA551_P_3_A0004_dsc_cmd", "mdss_dsi_panel_AA545_P_2_A0007_dsc_cmd";
		touchpanel,panel-coords = <20224 44480>;
		touchpanel,tx-rx-num = <17 38>;
		touchpanel,tp_ic_type = <2>;
		panel_type = <3 7>;
		firmware_name = "AA551";
		synaptics,power-on-state = <1>;
		synaptics,power-delay-ms = <200>;
		synaptics,irq-on-state = <0>;
		synaptics,reset-on-state = <0>;
		synaptics,reset-active-ms = <10>;
		synaptics,reset-delay-ms = <80>;
		synaptics,spi-mode = <0>;
		synaptics,spi-byte-delay-us = <0>;
		synaptics,spi-block-delay-us = <0>;
		S3910_PANEL7 {
			touchpanel,tx-rx-num = <18 39>;
		};
	};
};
